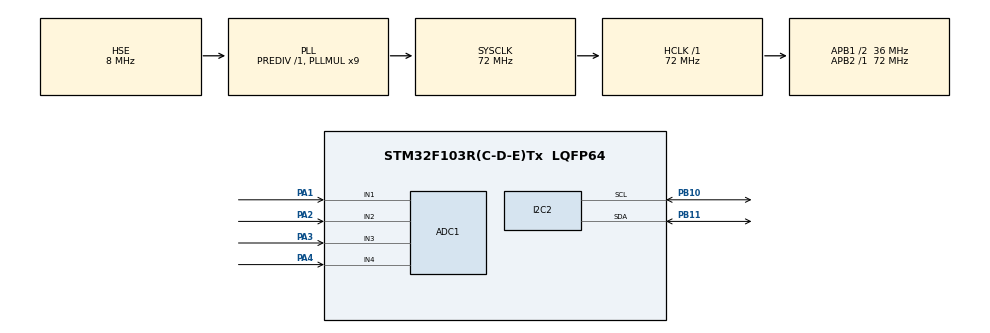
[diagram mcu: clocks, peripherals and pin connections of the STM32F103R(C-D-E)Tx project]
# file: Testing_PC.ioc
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ADC1.AWD1HighThreshold=4000
ADC1.Channel-0\#ChannelRegularConversion=ADC_CHANNEL_1
ADC1.Channel-1\#ChannelRegularConversion=ADC_CHANNEL_2
ADC1.Channel-2\#ChannelRegularConversion=ADC_CHANNEL_3
ADC1.Channel-3\#ChannelRegularConversion=ADC_CHANNEL_4
ADC1.ContinuousConvMode=ENABLE
ADC1.EnableAnalogWatchDog=true
ADC1.NbrOfConversion=4
ADC1.NbrOfConversionFlag=1
ADC1.Rank-0\#ChannelRegularConversion=1
ADC1.Rank-1\#ChannelRegularConversion=2
ADC1.Rank-2\#ChannelRegularConversion=3
ADC1.Rank-3\#ChannelRegularConversion=4
ADC1.SamplingTime-0\#ChannelRegularConversion=ADC_SAMPLETIME_28CYCLES_5
ADC1.SamplingTime-1\#ChannelRegularConversion=ADC_SAMPLETIME_28CYCLES_5
ADC1.SamplingTime-2\#ChannelRegularConversion=ADC_SAMPLETIME_28CYCLES_5
ADC1.SamplingTime-3\#ChannelRegularConversion=ADC_SAMPLETIME_28CYCLES_5
ADC1.WatchdogChannel=ADC_CHANNEL_1
ADC1.master=1
Mcu.Family=STM32F1
Mcu.Name=STM32F103R(C-D-E)Tx
Mcu.Package=LQFP64
NVIC.PriorityGroup=NVIC_PRIORITYGROUP_4
PA1.Signal=ADCx_IN1
PA13.Mode=Serial_Wire
PA13.Signal=SYS_JTMS-SWDIO
PA14.Mode=Serial_Wire
PA14.Signal=SYS_JTCK-SWCLK
PA2.Signal=ADCx_IN2
PA3.Signal=ADCx_IN3
PA4.Signal=ADCx_IN4
PB10.Mode=I2C
PB10.Signal=I2C2_SCL
PB11.Mode=I2C
PB11.Signal=I2C2_SDA
PC14-OSC32_IN.Mode=LSE-External-Oscillator
PC14-OSC32_IN.Signal=RCC_OSC32_IN
PC15-OSC32_OUT.Mode=LSE-External-Oscillator
PC15-OSC32_OUT.Signal=RCC_OSC32_OUT
PD0-OSC_IN.Mode=HSE-External-Oscillator
PD0-OSC_IN.Signal=RCC_OSC_IN
PD1-OSC_OUT.Mode=HSE-External-Oscillator
PD1-OSC_OUT.Signal=RCC_OSC_OUT
ProjectManager.HeapSize=0x200
ProjectManager.StackSize=0x400
ProjectManager.TargetToolchain=STM32CubeIDE
RCC.ADCPresc=RCC_ADCPCLK2_DIV6
RCC.AHBFreq_Value=72000000
RCC.APB1CLKDivider=RCC_HCLK_DIV2
RCC.APB1Freq_Value=36000000
RCC.APB1TimFreq_Value=72000000
RCC.APB2Freq_Value=72000000
RCC.APB2TimFreq_Value=72000000
RCC.HCLKFreq_Value=72000000
RCC.PLLMUL=RCC_PLL_MUL9
RCC.PLLSourceVirtual=RCC_PLLSOURCE_HSE
RCC.SYSCLKFreq_VALUE=72000000
RCC.SYSCLKSource=RCC_SYSCLKSOURCE_PLLCLK
RCC.USBFreq_Value=72000000
SH.ADCx_IN1.0=ADC1_IN1,IN1
SH.ADCx_IN2.0=ADC1_IN2,IN2
SH.ADCx_IN3.0=ADC1_IN3,IN3
SH.ADCx_IN4.0=ADC1_IN4,IN4
board=custom

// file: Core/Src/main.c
/* USER CODE BEGIN Header */
/**
  ******************************************************************************
  * @file           : main.c
  * @brief          : Main program body
  ******************************************************************************
  * @attention
  *
  * Copyright (c) 2025 STMicroelectronics.
  * All rights reserved.
  *
  * This software is licensed under terms that can be found in the LICENSE file
  * in the root directory of this software component.
  * If no LICENSE file comes with this software, it is provided AS-IS.
  *
  ******************************************************************************
  */
/* USER CODE END Header */
#include "main.h"

/* USER CODE BEGIN Includes */
#include "i2c.h"
/* USER CODE END Includes */

ADC_HandleTypeDef hadc1;

I2C_HandleTypeDef hi2c2;

void SystemClock_Config(void);
static void MX_GPIO_Init(void);
static void MX_ADC1_Init(void);
static void MX_I2C2_Init(void);

int main(void)
{

  /* MCU Configuration--------------------------------------------------------*/

  /* Reset of all peripherals, Initializes the Flash interface and the Systick. */
  HAL_Init();

  /* Configure the system clock */
  SystemClock_Config();

  /* Initialize all configured peripherals */
  MX_GPIO_Init();
  MX_ADC1_Init();
  MX_I2C2_Init();
  /* USER CODE BEGIN 2 */
//  ICM20948_Init(&hi2c2, ICM20948_ADDR); // R - Accel Initial
  ICM20948_Init(&hi2c2, ICM20948_ADDR_LOW); //L - accel intial
  /* USER CODE END 2 */

  /* Infinite loop */
  /* USER CODE BEGIN WHILE */
  while (1)
  {
	  ICM20948_Read_Accel(&hi2c2, &ICMDataR, ICM20948_ADDR);
	  ICM20948_Read_Accel(&hi2c2, &ICMDataL, ICM20948_ADDR_LOW);
	  HAL_Delay(50);
    /* USER CODE END WHILE */

  }
}

void SystemClock_Config(void)
{
  RCC_OscInitTypeDef RCC_OscInitStruct = {0};
  RCC_ClkInitTypeDef RCC_ClkInitStruct = {0};
  RCC_PeriphCLKInitTypeDef PeriphClkInit = {0};

  /** Initializes the RCC Oscillators according to the specified parameters
  * in the RCC_OscInitTypeDef structure.
  */
  RCC_OscInitStruct.OscillatorType = RCC_OSCILLATORTYPE_HSE;
  RCC_OscInitStruct.HSEState = RCC_HSE_ON;
  RCC_OscInitStruct.HSEPredivValue = RCC_HSE_PREDIV_DIV1;
  RCC_OscInitStruct.HSIState = RCC_HSI_ON;
  RCC_OscInitStruct.PLL.PLLState = RCC_PLL_ON;
  RCC_OscInitStruct.PLL.PLLSource = RCC_PLLSOURCE_HSE;
  RCC_OscInitStruct.PLL.PLLMUL = RCC_PLL_MUL9;
  if (HAL_RCC_OscConfig(&RCC_OscInitStruct) != HAL_OK)
  {
    Error_Handler();
  }

  /** Initializes the CPU, AHB and APB buses clocks
  */
  RCC_ClkInitStruct.ClockType = RCC_CLOCKTYPE_HCLK|RCC_CLOCKTYPE_SYSCLK
                              |RCC_CLOCKTYPE_PCLK1|RCC_CLOCKTYPE_PCLK2;
  RCC_ClkInitStruct.SYSCLKSource = RCC_SYSCLKSOURCE_PLLCLK;
  RCC_ClkInitStruct.AHBCLKDivider = RCC_SYSCLK_DIV1;
  RCC_ClkInitStruct.APB1CLKDivider = RCC_HCLK_DIV2;
  RCC_ClkInitStruct.APB2CLKDivider = RCC_HCLK_DIV1;

  if (HAL_RCC_ClockConfig(&RCC_ClkInitStruct, FLASH_LATENCY_2) != HAL_OK)
  {
    Error_Handler();
  }
  PeriphClkInit.PeriphClockSelection = RCC_PERIPHCLK_ADC;
  PeriphClkInit.AdcClockSelection = RCC_ADCPCLK2_DIV6;
  if (HAL_RCCEx_PeriphCLKConfig(&PeriphClkInit) != HAL_OK)
  {
    Error_Handler();
  }
}

static void MX_ADC1_Init(void)
{

  ADC_AnalogWDGConfTypeDef AnalogWDGConfig = {0};
  ADC_ChannelConfTypeDef sConfig = {0};

  /** Common config
  */
  hadc1.Instance = ADC1;
  hadc1.Init.ScanConvMode = ADC_SCAN_ENABLE;
  hadc1.Init.ContinuousConvMode = ENABLE;
  hadc1.Init.DiscontinuousConvMode = DISABLE;
  hadc1.Init.ExternalTrigConv = ADC_SOFTWARE_START;
  hadc1.Init.DataAlign = ADC_DATAALIGN_RIGHT;
  hadc1.Init.NbrOfConversion = 4;
  if (HAL_ADC_Init(&hadc1) != HAL_OK)
  {
    Error_Handler();
  }

  /** Configure Analog WatchDog 1
  */
  AnalogWDGConfig.WatchdogMode = ADC_ANALOGWATCHDOG_SINGLE_REG;
  AnalogWDGConfig.HighThreshold = 4000;
  AnalogWDGConfig.LowThreshold = 0;
  AnalogWDGConfig.Channel = ADC_CHANNEL_1;
  AnalogWDGConfig.ITMode = DISABLE;
  if (HAL_ADC_AnalogWDGConfig(&hadc1, &AnalogWDGConfig) != HAL_OK)
  {
    Error_Handler();
  }

  /** Configure Regular Channel
  */
  sConfig.Channel = ADC_CHANNEL_1;
  sConfig.Rank = ADC_REGULAR_RANK_1;
  sConfig.SamplingTime = ADC_SAMPLETIME_28CYCLES_5;
  if (HAL_ADC_ConfigChannel(&hadc1, &sConfig) != HAL_OK)
  {
    Error_Handler();
  }

  /** Configure Regular Channel
  */
  sConfig.Channel = ADC_CHANNEL_2;
  sConfig.Rank = ADC_REGULAR_RANK_2;
  if (HAL_ADC_ConfigChannel(&hadc1, &sConfig) != HAL_OK)
  {
    Error_Handler();
  }

  /** Configure Regular Channel
  */
  sConfig.Channel = ADC_CHANNEL_3;
  sConfig.Rank = ADC_REGULAR_RANK_3;
  if (HAL_ADC_ConfigChannel(&hadc1, &sConfig) != HAL_OK)
  {
    Error_Handler();
  }

  /** Configure Regular Channel
  */
  sConfig.Channel = ADC_CHANNEL_4;
  sConfig.Rank = ADC_REGULAR_RANK_4;
  if (HAL_ADC_ConfigChannel(&hadc1, &sConfig) != HAL_OK)
  {
    Error_Handler();
  }

}

static void MX_I2C2_Init(void)
{

  hi2c2.Instance = I2C2;
  hi2c2.Init.ClockSpeed = 100000;
  hi2c2.Init.DutyCycle = I2C_DUTYCYCLE_2;
  hi2c2.Init.OwnAddress1 = 0;
  hi2c2.Init.AddressingMode = I2C_ADDRESSINGMODE_7BIT;
  hi2c2.Init.DualAddressMode = I2C_DUALADDRESS_DISABLE;
  hi2c2.Init.OwnAddress2 = 0;
  hi2c2.Init.GeneralCallMode = I2C_GENERALCALL_DISABLE;
  hi2c2.Init.NoStretchMode = I2C_NOSTRETCH_DISABLE;
  if (HAL_I2C_Init(&hi2c2) != HAL_OK)
  {
    Error_Handler();
  }

}

static void MX_GPIO_Init(void)
{

  /* GPIO Ports Clock Enable */
  __HAL_RCC_GPIOC_CLK_ENABLE();
  __HAL_RCC_GPIOD_CLK_ENABLE();
  __HAL_RCC_GPIOA_CLK_ENABLE();
  __HAL_RCC_GPIOB_CLK_ENABLE();

}

void Error_Handler(void)
{
  __disable_irq();
  while (1)
  {
  }
}
